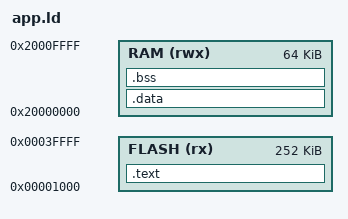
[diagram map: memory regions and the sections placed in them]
MEMORY
{
    FLASH (rx) : ORIGIN = 0x00001000, LENGTH = 0x0003f000
    RAM (rwx) : ORIGIN = 0x20000000, LENGTH = 0x00010000
}

SECTIONS
{
    .text :
    {
        _start_text = .;
        KEEP(*(.isr_vector))
        *(.text*)
        *(.rodata*)
        . = ALIGN(4);
        _end_text = .;
    } > FLASH

    _stored_data = .;

    .data : AT (_stored_data)
    {
        _start_data = .;
        KEEP(*(.data*))
        . = ALIGN(4);
        _end_data = .;
    } > RAM

    .bss :
    {
        _start_bss = .;
        *(.bss*)
        *(COMMON)
        . = ALIGN(4);
        _end_bss = .;
        _end = .;
    } > RAM
}

END_STACK = ORIGIN(RAM) + LENGTH(RAM);
